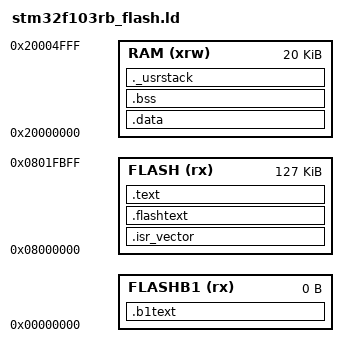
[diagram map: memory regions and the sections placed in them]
/*
 * $Id$
 *  
 * Copyright (C) 2010 Antoine Drouin <poinix@gmail.com>
 *
 * This file is part of Paparazzi.
 *
 * Paparazzi is free software; you can redistribute it and/or modify
 * it under the terms of the GNU General Public License as published by
 * the Free Software Foundation; either version 2, or (at your option)
 * any later version.
 *
 * Paparazzi is distributed in the hope that it will be useful,
 * but WITHOUT ANY WARRANTY; without even the implied warranty of
 * MERCHANTABILITY or FITNESS FOR A PARTICULAR PURPOSE.  See the
 * GNU General Public License for more details.
 *
 * You should have received a copy of the GNU General Public License
 * along with Paparazzi; see the file COPYING.  If not, write to
 * the Free Software Foundation, 59 Temple Place - Suite 330,
 * Boston, MA 02111-1307, USA. 
 */

/* Memory Spaces Definitions */
MEMORY
{                        
  RAM     (xrw): ORIGIN = 0x20000000, LENGTH = 20K
  /* last page (1k) flash for persistent settings */
  FLASH   (rx) : ORIGIN = 0x8000000,  LENGTH = 127K
  FLASHB1 (rx) : ORIGIN = 0x00000000, LENGTH = 0
}

/* User mode stack top */
_estack = 0x20005000;

/* Stack size and address definitions */
__Stack_Size = 0x1000 ;

PROVIDE ( _Stack_Size = __Stack_Size ) ;

__Stack_Init = _estack  - __Stack_Size ;

PROVIDE ( _Stack_Init = __Stack_Init ) ;

/* Enforce a linker error if there is not enough space left in ram for the stack */
_Minimum_Stack_Size = 0x800 ;

/* Check valid alignment for VTOR */
ASSERT(ORIGIN(FLASH) == ALIGN(ORIGIN(FLASH), 0x80), "Start of memory region flash not aligned for startup vector table");

/* Sections Definitions */

SECTIONS
{
    /* for Cortex devices, the beginning of the startup code is stored in the .isr_vector section, which goes to FLASH */
    .isr_vector :
    {
        . = ALIGN(4);
        KEEP(*(.isr_vector)) /* Startup code */
	. = ALIGN(4);
    } >FLASH

    /* for some STRx devices, the beginning of the startup code is stored in the .flashtext section, which goes to FLASH */
    .flashtext :
    {
	. = ALIGN(4);
        *(.flashtext)        /* Startup code */
	. = ALIGN(4);
    } >FLASH


    /* the program code is stored in the .text section, which goes to Flash */
    .text :
    {
        . = ALIGN(4);

        *(.text)             /* remaining code */
        *(.text.*)           /* remaining code */
        *(.rodata)           /* read-only data (constants) */
        *(.rodata*)
        *(.glue_7)
        *(.glue_7t)

        . = ALIGN(4);
   	_etext = .;
	/* This is used by the startup in order to initialize the .data secion */
   	_sidata = _etext;
    } >FLASH



    /* This is the initialized data section
    The program executes knowing that the data is in the RAM
    but the loader puts the initial values in the FLASH (inidata).
    It is one task of the startup to copy the initial values from FLASH to RAM. */
    .data  : AT ( _sidata )
    {
        . = ALIGN(4);
        /* This is used by the startup in order to initialize the .data secion */
        _sdata = . ;

        *(.data)
        *(.data.*)

        . = ALIGN(4);
	/* This is used by the startup in order to initialize the .data secion */
   	_edata = . ;
    } >RAM



    /* This is the uninitialized data section */
    .bss :
    {
        . = ALIGN(4);
        /* This is used by the startup in order to initialize the .bss secion */
        _sbss = .;

        *(.dynbss)
        *(.bss .bss.* .gnu.linkonce.b.*)
	  /*        *(.bss) */
        *(COMMON)

        . = ALIGN(4);
	/* This is used by the startup in order to initialize the .bss secion */
   	_ebss = . ;
    } >RAM

    PROVIDE ( end = _ebss );
    PROVIDE ( _end = _ebss );

    /* This is the user stack section
    This is just to check that there is enough RAM left for the User mode stack
    It should generate an error if it's full.
     */
    ._usrstack :
    {
        . = ALIGN(4);
        _susrstack = . ;
        . = . + _Minimum_Stack_Size ;
        . = ALIGN(4);
        _eusrstack = . ;
    } >RAM

   .b1text :
    {
        *(.b1text)                   /* remaining code */
        *(.b1rodata)                 /* read-only data (constants) */
        *(.b1rodata*)
    } >FLASHB1

    __exidx_start = .;
    .ARM.exidx   : { *(.ARM.exidx* .gnu.linkonce.armexidx.*) }
   __exidx_end = .;

    /* after that it's only debugging information. */

    /* remove the debugging information from the standard libraries */
    /DISCARD/ :
    {
     libc.a ( * )
     libm.a ( * )
     libgcc.a ( * )
     }

    /* Stabs debugging sections.  */
    .stab          0 : { *(.stab) }
    .stabstr       0 : { *(.stabstr) }
    .stab.excl     0 : { *(.stab.excl) }
    .stab.exclstr  0 : { *(.stab.exclstr) }
    .stab.index    0 : { *(.stab.index) }
    .stab.indexstr 0 : { *(.stab.indexstr) }
    .comment       0 : { *(.comment) }
    /* DWARF debug sections.
       Symbols in the DWARF debugging sections are relative to the beginning
       of the section so we begin them at 0.*/
    /* DWARF 1 */
    .debug          0 : { *(.debug) }
    .line           0 : { *(.line) }
    /* GNU DWARF 1 extensions */
    .debug_srcinfo  0 : { *(.debug_srcinfo) }
    .debug_sfnames  0 : { *(.debug_sfnames) }
    /* DWARF 1.1 and DWARF 2 */
    .debug_aranges  0 : { *(.debug_aranges) }
    .debug_pubnames 0 : { *(.debug_pubnames) }
    /* DWARF 2 */
    .debug_info     0 : { *(.debug_info .gnu.linkonce.wi.*) }
    .debug_abbrev   0 : { *(.debug_abbrev) }
    .debug_line     0 : { *(.debug_line) }
    .debug_frame    0 : { *(.debug_frame) }
    .debug_str      0 : { *(.debug_str) }
    .debug_loc      0 : { *(.debug_loc) }
    .debug_macinfo  0 : { *(.debug_macinfo) }
    /* SGI/MIPS DWARF 2 extensions */
    .debug_weaknames 0 : { *(.debug_weaknames) }
    .debug_funcnames 0 : { *(.debug_funcnames) }
    .debug_typenames 0 : { *(.debug_typenames) }
    .debug_varnames  0 : { *(.debug_varnames) }
}
